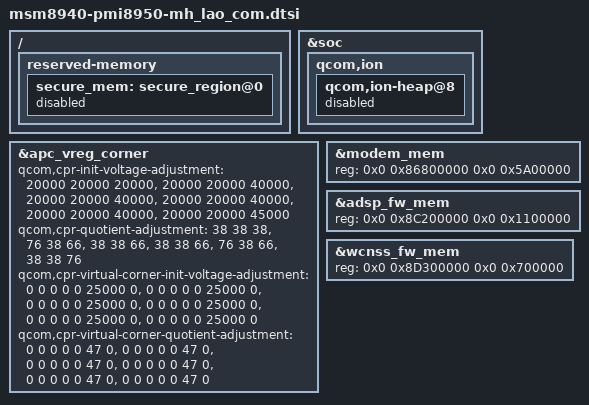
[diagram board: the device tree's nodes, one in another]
/*
 * Copyright (c) 2016, The Linux Foundation. All rights reserved.
 *
 * This program is free software; you can redistribute it and/or modify
 * it under the terms of the GNU General Public License version 2 and
 * only version 2 as published by the Free Software Foundation.
 *
 * This program is distributed in the hope that it will be useful,
 * but WITHOUT ANY WARRANTY; without even the implied warranty of
 * MERCHANTABILITY or FITNESS FOR A PARTICULAR PURPOSE.  See the
 * GNU General Public License for more details.
 */

#include "msm8940-mh_lao_com-pinctrl.dtsi"
#include "msm8940-mh_lao_com-camera.dtsi"
#include "msm8940-mh_lao_com-panel.dtsi"
#include "msm8940-mh_lao_com-sound.dtsi"
#include "msm8940-mh_lao_com-misc.dtsi"
#include "msm8940-pmi8950-mh_lao_com-pm.dtsi"
#include "msm8940-mh_lao_com-touch.dtsi"
#include "msm8940-pmi8950-mh_lao_com-usb.dtsi"
#include "msm8940-mh_lao_com-nfc.dtsi"

/ {
	reserved-memory {
		secure_mem: secure_region@0 {
			status = "disabled";
		};
	};
};

&soc {
	qcom,ion {
		qcom,ion-heap@8 { /* CP_MM HEAP  */
			status = "disabled";
		};
	};
};

&apc_vreg_corner {
	/delete-property/ qcom,cpr-init-voltage-adjustment;
	/delete-property/ qcom,cpr-quotient-adjustment;

	qcom,cpr-init-voltage-adjustment =
		<20000 20000 20000>,
		<20000 20000 40000>,
		<20000 20000 40000>,
		<20000 20000 40000>,
		<20000 20000 40000>,
		<20000 20000 45000>;

	qcom,cpr-quotient-adjustment =
		<38    38    38>,
		<76    38    66>, /* SVSP(20mv); TURBO(15mv); KV(1.9) */
		<38    38    66>, /* TURBO(10mv); KV(1.9) */
		<38    38    66>, /* TURBO(15mv); KV(1.9) */
		<76    38    66>, /* SVSP(20mv); TURBO(15mv); KV(1.9) */
		<38    38    76>; /* TURBO(15mv); KV(1.9) */

	qcom,cpr-virtual-corner-init-voltage-adjustment =
		<0    0    0   0   0    25000     0>,
		<0    0    0   0   0    25000     0>,
		<0    0    0   0   0    25000     0>,
		<0    0    0   0   0    25000     0>,
		<0    0    0   0   0    25000     0>,
		<0    0    0   0   0    25000     0>;

	qcom,cpr-virtual-corner-quotient-adjustment =
		<0    0    0    0    0    47     0>,
		<0    0    0    0    0    47     0>,
		<0    0    0    0    0    47     0>,
		<0    0    0    0    0    47     0>,
		<0    0    0    0    0    47     0>,
		<0    0    0    0    0    47     0>;
};

&modem_mem {
    reg = <0x0 0x86800000 0x0 0x5A00000>;
};

&adsp_fw_mem {
    reg = <0x0 0x8C200000 0x0 0x1100000>;
};

&wcnss_fw_mem {
    reg = <0x0 0x8D300000 0x0 0x700000>;
};
